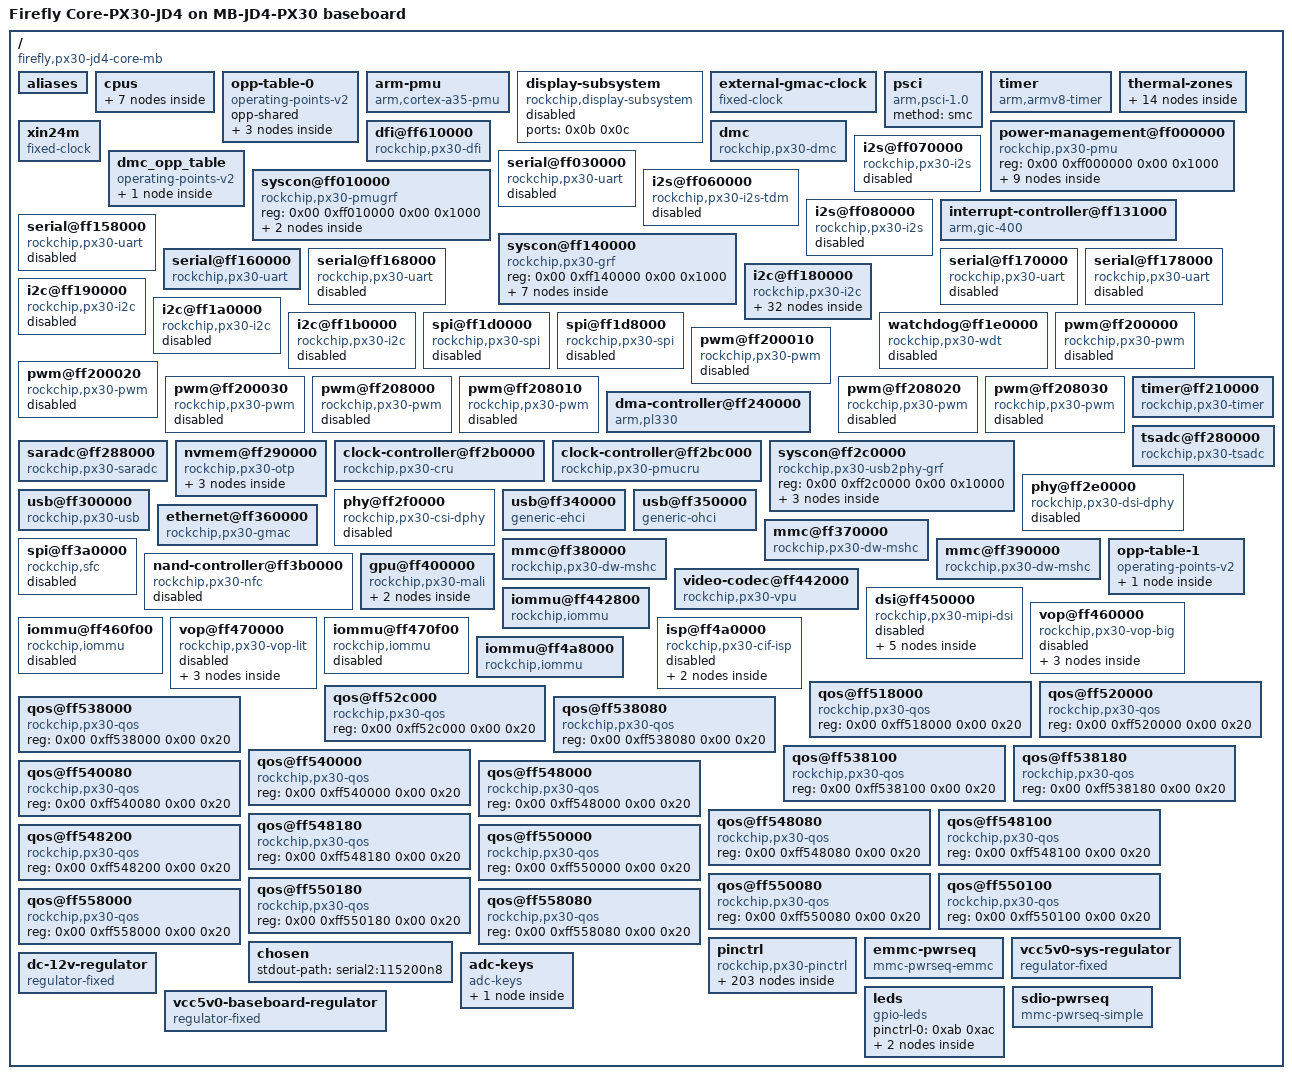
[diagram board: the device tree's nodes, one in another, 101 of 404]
/dts-v1/;

/ {
	compatible = "firefly,px30-jd4-core-mb\0firefly,px30-jd4-core\0rockchip,px30";
	interrupt-parent = <0x01>;
	#address-cells = <0x02>;
	#size-cells = <0x02>;
	model = "Firefly Core-PX30-JD4 on MB-JD4-PX30 baseboard";

	aliases {
		ethernet0 = "/ethernet@ff360000";
		i2c0 = "/i2c@ff180000";
		i2c1 = "/i2c@ff190000";
		i2c2 = "/i2c@ff1a0000";
		i2c3 = "/i2c@ff1b0000";
		serial0 = "/serial@ff030000";
		serial1 = "/serial@ff158000";
		serial2 = "/serial@ff160000";
		serial3 = "/serial@ff168000";
		serial4 = "/serial@ff170000";
		serial5 = "/serial@ff178000";
		spi0 = "/spi@ff1d0000";
		spi1 = "/spi@ff1d8000";
		mmc0 = "/mmc@ff370000";
		mmc1 = "/mmc@ff380000";
		mmc2 = "/mmc@ff390000";
	};

	cpus {
		#address-cells = <0x02>;
		#size-cells = <0x00>;

		cpu@0 {
			device_type = "cpu";
			compatible = "arm,cortex-a35";
			reg = <0x00 0x00>;
			enable-method = "psci";
			clocks = <0x02 0x07>;
			#cooling-cells = <0x02>;
			cpu-idle-states = <0x03 0x04>;
			dynamic-power-coefficient = <0x5a>;
			operating-points-v2 = <0x05>;
			cpu-supply = <0x06>;
			phandle = <0x07>;
		};

		cpu@1 {
			device_type = "cpu";
			compatible = "arm,cortex-a35";
			reg = <0x00 0x01>;
			enable-method = "psci";
			clocks = <0x02 0x07>;
			#cooling-cells = <0x02>;
			cpu-idle-states = <0x03 0x04>;
			dynamic-power-coefficient = <0x5a>;
			operating-points-v2 = <0x05>;
			cpu-supply = <0x06>;
			phandle = <0x08>;
		};

		cpu@2 {
			device_type = "cpu";
			compatible = "arm,cortex-a35";
			reg = <0x00 0x02>;
			enable-method = "psci";
			clocks = <0x02 0x07>;
			#cooling-cells = <0x02>;
			cpu-idle-states = <0x03 0x04>;
			dynamic-power-coefficient = <0x5a>;
			operating-points-v2 = <0x05>;
			cpu-supply = <0x06>;
			phandle = <0x09>;
		};

		cpu@3 {
			device_type = "cpu";
			compatible = "arm,cortex-a35";
			reg = <0x00 0x03>;
			enable-method = "psci";
			clocks = <0x02 0x07>;
			#cooling-cells = <0x02>;
			cpu-idle-states = <0x03 0x04>;
			dynamic-power-coefficient = <0x5a>;
			operating-points-v2 = <0x05>;
			cpu-supply = <0x06>;
			phandle = <0x0a>;
		};

		idle-states {
			entry-method = "psci";

			cpu-sleep {
				compatible = "arm,idle-state";
				local-timer-stop;
				arm,psci-suspend-param = <0x10000>;
				entry-latency-us = <0x78>;
				exit-latency-us = <0xfa>;
				min-residency-us = <0x384>;
				phandle = <0x03>;
			};

			cluster-sleep {
				compatible = "arm,idle-state";
				local-timer-stop;
				arm,psci-suspend-param = <0x1010000>;
				entry-latency-us = <0x190>;
				exit-latency-us = <0x1f4>;
				min-residency-us = <0x7d0>;
				phandle = <0x04>;
			};
		};
	};

	opp-table-0 {
		compatible = "operating-points-v2";
		opp-shared;
		phandle = <0x05>;

		opp-1008000000 {
			opp-hz = <0x00 0x3c14dc00>;
			opp-microvolt = <0x11edd8 0x11edd8 0x149970>;
			clock-latency-ns = <0x9c40>;
		};

		opp-1296000000 {
			opp-hz = <0x00 0x4d3f6400>;
			opp-microvolt = <0x149970 0x149970 0x149970>;
			clock-latency-ns = <0x9c40>;
		};

		opp-1416000000 {
			opp-hz = <0x00 0x54667200>;
			opp-microvolt = <0x149970 0x149970 0x149970>;
			clock-latency-ns = <0x9c40>;
			turbo-mode;
		};
	};

	arm-pmu {
		compatible = "arm,cortex-a35-pmu";
		interrupts = <0x00 0x64 0x04 0x00 0x65 0x04 0x00 0x66 0x04 0x00 0x67 0x04>;
		interrupt-affinity = <0x07 0x08 0x09 0x0a>;
	};

	display-subsystem {
		compatible = "rockchip,display-subsystem";
		ports = <0x0b 0x0c>;
		status = "disabled";
	};

	external-gmac-clock {
		compatible = "fixed-clock";
		clock-frequency = <0x2faf080>;
		clock-output-names = "gmac_clkin";
		#clock-cells = <0x00>;
	};

	psci {
		compatible = "arm,psci-1.0";
		method = "smc";
	};

	timer {
		compatible = "arm,armv8-timer";
		interrupts = <0x01 0x0d 0xf04 0x01 0x0e 0xf04 0x01 0x0b 0xf04 0x01 0x0a 0xf04>;
	};

	thermal-zones {

		soc-thermal {
			polling-delay-passive = <0x14>;
			polling-delay = <0x3e8>;
			sustainable-power = <0x2ee>;
			thermal-sensors = <0x0d 0x00>;

			trips {

				trip-point-0 {
					temperature = <0x11170>;
					hysteresis = <0x7d0>;
					type = "passive";
				};

				trip-point-1 {
					temperature = <0x14c08>;
					hysteresis = <0x7d0>;
					type = "passive";
					phandle = <0x0e>;
				};

				soc-crit {
					temperature = <0x1c138>;
					hysteresis = <0x7d0>;
					type = "critical";
				};
			};

			cooling-maps {

				map0 {
					trip = <0x0e>;
					cooling-device = <0x07 0xffffffff 0xffffffff>;
					contribution = <0x1000>;
				};
			};
		};

		gpu-thermal {
			polling-delay-passive = <0x64>;
			polling-delay = <0x3e8>;
			thermal-sensors = <0x0d 0x01>;

			trips {

				gpu-threshold {
					temperature = <0x11170>;
					hysteresis = <0x7d0>;
					type = "passive";
				};

				gpu-target {
					temperature = <0x14c08>;
					hysteresis = <0x7d0>;
					type = "passive";
					phandle = <0x0f>;
				};

				gpu-crit {
					temperature = <0x1c138>;
					hysteresis = <0x7d0>;
					type = "critical";
				};
			};

			cooling-maps {

				map0 {
					trip = <0x0f>;
					cooling-device = <0x10 0xffffffff 0xffffffff>;
				};
			};
		};
	};

	xin24m {
		compatible = "fixed-clock";
		#clock-cells = <0x00>;
		clock-frequency = <0x16e3600>;
		clock-output-names = "xin24m";
		phandle = <0x71>;
	};

	power-management@ff000000 {
		compatible = "rockchip,px30-pmu\0syscon\0simple-mfd";
		reg = <0x00 0xff000000 0x00 0x1000>;

		power-controller {
			compatible = "rockchip,px30-power-controller";
			#power-domain-cells = <0x01>;
			#address-cells = <0x01>;
			#size-cells = <0x00>;
			phandle = <0x73>;

			power-domain@5 {
				reg = <0x05>;
				clocks = <0x02 0x103 0x02 0x102 0x02 0x3c>;
				pm_qos = <0x11 0x12>;
				#power-domain-cells = <0x00>;
			};

			power-domain@7 {
				reg = <0x07>;
				clocks = <0x02 0xf7 0x02 0x3b>;
				pm_qos = <0x13>;
				#power-domain-cells = <0x00>;
			};

			power-domain@9 {
				reg = <0x09>;
				clocks = <0x02 0xb2 0x02 0x143 0x02 0x40 0x02 0x3f>;
				pm_qos = <0x14>;
				#power-domain-cells = <0x00>;
			};

			power-domain@10 {
				reg = <0x0a>;
				clocks = <0x02 0xfe 0x02 0x100 0x02 0xff 0x02 0x101 0x02 0x39 0x02 0x37 0x02 0x38 0x02 0x3a>;
				pm_qos = <0x15 0x16 0x17 0x18>;
				#power-domain-cells = <0x00>;
			};

			power-domain@11 {
				reg = <0x0b>;
				clocks = <0x02 0xaf 0x02 0xf4 0x02 0x4b>;
				pm_qos = <0x19 0x1a>;
				#power-domain-cells = <0x00>;
			};

			power-domain@12 {
				reg = <0x0c>;
				clocks = <0x02 0xb7 0x02 0xb5 0x02 0xb6 0x02 0x96 0x02 0x97 0x02 0xfd 0x02 0xfb 0x02 0xfc 0x02 0x144 0x02 0x35 0x02 0x36>;
				pm_qos = <0x1b 0x1c 0x1d 0x1e>;
				#power-domain-cells = <0x00>;
			};

			power-domain@13 {
				reg = <0x0d>;
				clocks = <0x02 0xb3 0x02 0xb4 0x02 0xf9 0x02 0xfa 0x02 0x33>;
				pm_qos = <0x1f 0x20 0x21 0x22 0x23>;
				#power-domain-cells = <0x00>;
			};

			power-domain@14 {
				reg = <0x0e>;
				clocks = <0x02 0x49>;
				pm_qos = <0x24>;
				#power-domain-cells = <0x00>;
			};
		};
	};

	dfi@ff610000 {
		reg = <0x00 0xff610000 0x00 0x400>;
		compatible = "rockchip,px30-dfi";
		rockchip,pmu = <0x25>;
		status = "okay";
		phandle = <0x26>;
	};

	dmc {
		compatible = "rockchip,px30-dmc";
		devfreq-events = <0x26>;
		clocks = <0x02 0x54>;
		clock-names = "dmc_clk";
		operating-points-v2 = <0x27>;
		uptreshold = <0x28>;
		downdifferential = <0x14>;
		status = "okay";
	};

	dmc_opp_table {
		compatible = "operating-points-v2";
		phandle = <0x27>;

		opp-924000000 {
			opp-hz = <0x00 0x37131f00>;
			opp-microvolt = <0x112a88>;
		};
	};

	syscon@ff010000 {
		compatible = "rockchip,px30-pmugrf\0syscon\0simple-mfd";
		reg = <0x00 0xff010000 0x00 0x1000>;
		#address-cells = <0x01>;
		#size-cells = <0x01>;
		phandle = <0x25>;

		io-domains {
			compatible = "rockchip,px30-pmu-io-voltage-domain";
			status = "okay";
			pmuio1-supply = <0x28>;
			pmuio2-supply = <0x28>;
		};

		reboot-mode {
			compatible = "syscon-reboot-mode";
			offset = <0x200>;
			mode-bootloader = <0x5242c301>;
			mode-fastboot = <0x5242c309>;
			mode-loader = <0x5242c301>;
			mode-normal = <0x5242c300>;
			mode-recovery = <0x5242c303>;
		};
	};

	serial@ff030000 {
		compatible = "rockchip,px30-uart\0snps,dw-apb-uart";
		reg = <0x00 0xff030000 0x00 0x100>;
		interrupts = <0x00 0x0f 0x04>;
		clocks = <0x29 0x06 0x29 0x15>;
		clock-names = "baudclk\0apb_pclk";
		dmas = <0x2a 0x00 0x2a 0x01>;
		dma-names = "tx\0rx";
		reg-shift = <0x02>;
		reg-io-width = <0x04>;
		pinctrl-names = "default";
		pinctrl-0 = <0x2b 0x2c 0x2d>;
		status = "disabled";
	};

	i2s@ff060000 {
		compatible = "rockchip,px30-i2s-tdm";
		reg = <0x00 0xff060000 0x00 0x1000>;
		interrupts = <0x00 0x0c 0x04>;
		clocks = <0x02 0x10 0x02 0x12 0x02 0x106>;
		clock-names = "mclk_tx\0mclk_rx\0hclk";
		dmas = <0x2a 0x10 0x2a 0x11>;
		dma-names = "tx\0rx";
		rockchip,grf = <0x2e>;
		resets = <0x02 0x84 0x02 0xbf>;
		reset-names = "tx-m\0rx-m";
		pinctrl-names = "default";
		pinctrl-0 = <0x2f 0x30 0x31 0x32 0x33 0x34 0x35 0x36 0x37 0x38 0x39 0x3a>;
		#sound-dai-cells = <0x00>;
		status = "disabled";
	};

	i2s@ff070000 {
		compatible = "rockchip,px30-i2s\0rockchip,rk3066-i2s";
		reg = <0x00 0xff070000 0x00 0x1000>;
		interrupts = <0x00 0x0d 0x04>;
		clocks = <0x02 0x14 0x02 0x107>;
		clock-names = "i2s_clk\0i2s_hclk";
		dmas = <0x2a 0x12 0x2a 0x13>;
		dma-names = "tx\0rx";
		pinctrl-names = "default";
		pinctrl-0 = <0x3b 0x3c 0x3d 0x3e>;
		#sound-dai-cells = <0x00>;
		status = "disabled";
	};

	i2s@ff080000 {
		compatible = "rockchip,px30-i2s\0rockchip,rk3066-i2s";
		reg = <0x00 0xff080000 0x00 0x1000>;
		interrupts = <0x00 0x0e 0x04>;
		clocks = <0x02 0x16 0x02 0x108>;
		clock-names = "i2s_clk\0i2s_hclk";
		dmas = <0x2a 0x14 0x2a 0x15>;
		dma-names = "tx\0rx";
		pinctrl-names = "default";
		pinctrl-0 = <0x3f 0x40 0x41 0x42>;
		#sound-dai-cells = <0x00>;
		status = "disabled";
	};

	interrupt-controller@ff131000 {
		compatible = "arm,gic-400";
		#interrupt-cells = <0x03>;
		#address-cells = <0x00>;
		interrupt-controller;
		reg = <0x00 0xff131000 0x00 0x1000 0x00 0xff132000 0x00 0x2000 0x00 0xff134000 0x00 0x2000 0x00 0xff136000 0x00 0x2000>;
		interrupts = <0x01 0x09 0xf04>;
		phandle = <0x01>;
	};

	syscon@ff140000 {
		compatible = "rockchip,px30-grf\0syscon\0simple-mfd";
		reg = <0x00 0xff140000 0x00 0x1000>;
		#address-cells = <0x01>;
		#size-cells = <0x01>;
		phandle = <0x2e>;

		io-domains {
			compatible = "rockchip,px30-io-voltage-domain";
			status = "okay";
			vccio1-supply = <0x43>;
			vccio2-supply = <0x44>;
			vccio3-supply = <0x45>;
			vccio4-supply = <0x28>;
			vccio5-supply = <0x45>;
			vccio6-supply = <0x43>;
		};

		lvds {
			compatible = "rockchip,px30-lvds";
			phys = <0x46>;
			phy-names = "dphy";
			rockchip,grf = <0x2e>;
			rockchip,output = "lvds";
			status = "disabled";

			ports {
				#address-cells = <0x01>;
				#size-cells = <0x00>;

				port@0 {
					reg = <0x00>;
					#address-cells = <0x01>;
					#size-cells = <0x00>;

					endpoint@0 {
						reg = <0x00>;
						remote-endpoint = <0x47>;
						phandle = <0x98>;
					};

					endpoint@1 {
						reg = <0x01>;
						remote-endpoint = <0x48>;
						phandle = <0x9b>;
					};
				};

				port@1 {
					reg = <0x01>;
				};
			};
		};
	};

	serial@ff158000 {
		compatible = "rockchip,px30-uart\0snps,dw-apb-uart";
		reg = <0x00 0xff158000 0x00 0x100>;
		interrupts = <0x00 0x10 0x04>;
		clocks = <0x02 0x18 0x02 0x149>;
		clock-names = "baudclk\0apb_pclk";
		dmas = <0x2a 0x02 0x2a 0x03>;
		dma-names = "tx\0rx";
		reg-shift = <0x02>;
		reg-io-width = <0x04>;
		pinctrl-names = "default";
		pinctrl-0 = <0x49 0x4a 0x4b>;
		status = "disabled";
	};

	serial@ff160000 {
		compatible = "rockchip,px30-uart\0snps,dw-apb-uart";
		reg = <0x00 0xff160000 0x00 0x100>;
		interrupts = <0x00 0x11 0x04>;
		clocks = <0x02 0x19 0x02 0x14a>;
		clock-names = "baudclk\0apb_pclk";
		dmas = <0x2a 0x04 0x2a 0x05>;
		dma-names = "tx\0rx";
		reg-shift = <0x02>;
		reg-io-width = <0x04>;
		pinctrl-names = "default";
		pinctrl-0 = <0x4c>;
		status = "okay";
	};

	serial@ff168000 {
		compatible = "rockchip,px30-uart\0snps,dw-apb-uart";
		reg = <0x00 0xff168000 0x00 0x100>;
		interrupts = <0x00 0x12 0x04>;
		clocks = <0x02 0x1a 0x02 0x14b>;
		clock-names = "baudclk\0apb_pclk";
		dmas = <0x2a 0x06 0x2a 0x07>;
		dma-names = "tx\0rx";
		reg-shift = <0x02>;
		reg-io-width = <0x04>;
		pinctrl-names = "default";
		pinctrl-0 = <0x4d 0x4e 0x4f>;
		status = "disabled";
	};

	serial@ff170000 {
		compatible = "rockchip,px30-uart\0snps,dw-apb-uart";
		reg = <0x00 0xff170000 0x00 0x100>;
		interrupts = <0x00 0x13 0x04>;
		clocks = <0x02 0x1b 0x02 0x14c>;
		clock-names = "baudclk\0apb_pclk";
		dmas = <0x2a 0x08 0x2a 0x09>;
		dma-names = "tx\0rx";
		reg-shift = <0x02>;
		reg-io-width = <0x04>;
		pinctrl-names = "default";
		pinctrl-0 = <0x50 0x51 0x52>;
		status = "disabled";
	};

	serial@ff178000 {
		compatible = "rockchip,px30-uart\0snps,dw-apb-uart";
		reg = <0x00 0xff178000 0x00 0x100>;
		interrupts = <0x00 0x14 0x04>;
		clocks = <0x02 0x1c 0x02 0x14d>;
		clock-names = "baudclk\0apb_pclk";
		dmas = <0x2a 0x0a 0x2a 0x0b>;
		dma-names = "tx\0rx";
		reg-shift = <0x02>;
		reg-io-width = <0x04>;
		pinctrl-names = "default";
		pinctrl-0 = <0x53 0x54 0x55>;
		status = "disabled";
	};

	i2c@ff180000 {
		compatible = "rockchip,px30-i2c\0rockchip,rk3399-i2c";
		reg = <0x00 0xff180000 0x00 0x1000>;
		clocks = <0x02 0x1d 0x02 0x14e>;
		clock-names = "i2c\0pclk";
		interrupts = <0x00 0x07 0x04>;
		pinctrl-names = "default";
		pinctrl-0 = <0x56>;
		#address-cells = <0x01>;
		#size-cells = <0x00>;
		status = "okay";

		pmic@20 {
			compatible = "rockchip,rk809";
			reg = <0x20>;
			interrupt-parent = <0x57>;
			interrupts = <0x07 0x08>;
			pinctrl-names = "default";
			pinctrl-0 = <0x58>;
			rockchip,system-power-controller;
			wakeup-source;
			#clock-cells = <0x00>;
			clock-output-names = "xin32k";
			vcc1-supply = <0x59>;
			vcc2-supply = <0x59>;
			vcc3-supply = <0x59>;
			vcc4-supply = <0x59>;
			vcc5-supply = <0x5a>;
			vcc6-supply = <0x5a>;
			vcc7-supply = <0x5a>;
			vcc8-supply = <0x5a>;
			vcc9-supply = <0x59>;

			regulators {

				DCDC_REG1 {
					regulator-name = "vdd_log";
					regulator-min-microvolt = <0xe7ef0>;
					regulator-max-microvolt = <0x149970>;
					regulator-ramp-delay = <0x1771>;
					regulator-always-on;
					regulator-boot-on;
					phandle = <0x92>;

					regulator-state-mem {
						regulator-on-in-suspend;
						regulator-suspend-microvolt = <0xe7ef0>;
					};
				};

				DCDC_REG2 {
					regulator-name = "vdd_arm";
					regulator-min-microvolt = <0xe7ef0>;
					regulator-max-microvolt = <0x149970>;
					regulator-ramp-delay = <0x1771>;
					regulator-always-on;
					regulator-boot-on;
					phandle = <0x06>;

					regulator-state-mem {
						regulator-off-in-suspend;
						regulator-suspend-microvolt = <0xe7ef0>;
					};
				};

				DCDC_REG3 {
					regulator-name = "vcc_ddr";
					regulator-always-on;
					regulator-boot-on;

					regulator-state-mem {
						regulator-on-in-suspend;
					};
				};

				DCDC_REG4 {
					regulator-name = "vcc_3v0";
					regulator-min-microvolt = <0x2dc6c0>;
					regulator-max-microvolt = <0x2dc6c0>;
					regulator-always-on;
					regulator-boot-on;
					phandle = <0x45>;

					regulator-state-mem {
						regulator-on-in-suspend;
						regulator-suspend-microvolt = <0x2dc6c0>;
					};
				};

				DCDC_REG5 {
					regulator-name = "vcc3v3_sys";
					regulator-min-microvolt = <0x325aa0>;
					regulator-max-microvolt = <0x325aa0>;
					regulator-always-on;
					regulator-boot-on;
					phandle = <0x5a>;

					regulator-state-mem {
						regulator-on-in-suspend;
						regulator-suspend-microvolt = <0x325aa0>;
					};
				};

				LDO_REG1 {
					regulator-name = "vcc_1v0";
					regulator-min-microvolt = <0xf4240>;
					regulator-max-microvolt = <0xf4240>;
					regulator-always-on;
					regulator-boot-on;

					regulator-state-mem {
						regulator-on-in-suspend;
						regulator-suspend-microvolt = <0xf4240>;
					};
				};

				LDO_REG2 {
					regulator-name = "vcc_1v8";
					regulator-min-microvolt = <0x1b7740>;
					regulator-max-microvolt = <0x1b7740>;
					regulator-always-on;
					regulator-boot-on;
					phandle = <0x43>;

					regulator-state-mem {
						regulator-on-in-suspend;
						regulator-suspend-microvolt = <0x1b7740>;
					};
				};

				LDO_REG3 {
					regulator-name = "vdd_1v0";
					regulator-min-microvolt = <0xf4240>;
					regulator-max-microvolt = <0xf4240>;
					regulator-always-on;
					regulator-boot-on;

					regulator-state-mem {
						regulator-on-in-suspend;
						regulator-suspend-microvolt = <0xf4240>;
					};
				};

				LDO_REG4 {
					regulator-name = "vcc3v0_pmu";
					regulator-min-microvolt = <0x2dc6c0>;
					regulator-max-microvolt = <0x2dc6c0>;
					regulator-always-on;
					regulator-boot-on;
					phandle = <0x28>;

					regulator-state-mem {
						regulator-on-in-suspend;
						regulator-suspend-microvolt = <0x2dc6c0>;
					};
				};

				LDO_REG5 {
					regulator-name = "vccio_sd";
					regulator-min-microvolt = <0x1b7740>;
					regulator-max-microvolt = <0x325aa0>;
					regulator-always-on;
					regulator-boot-on;
					phandle = <0x44>;

					regulator-state-mem {
						regulator-on-in-suspend;
						regulator-suspend-microvolt = <0x325aa0>;
					};
				};

				LDO_REG6 {
					regulator-name = "vcc_sd";
					regulator-min-microvolt = <0x325aa0>;
					regulator-max-microvolt = <0x325aa0>;
					regulator-boot-on;
					phandle = <0x7d>;

					regulator-state-mem {
						regulator-on-in-suspend;
						regulator-suspend-microvolt = <0x325aa0>;
					};
				};

				LDO_REG7 {
					regulator-name = "vcc2v8_dvp";
					regulator-min-microvolt = <0x2ab980>;
					regulator-max-microvolt = <0x2ab980>;
					regulator-boot-on;

					regulator-state-mem {
						regulator-off-in-suspend;
						regulator-suspend-microvolt = <0x2ab980>;
					};
				};

				LDO_REG8 {
					regulator-name = "vcc1v8_dvp";
					regulator-min-microvolt = <0x1b7740>;
					regulator-max-microvolt = <0x1b7740>;
					regulator-boot-on;

					regulator-state-mem {
						regulator-on-in-suspend;
						regulator-suspend-microvolt = <0x1b7740>;
					};
				};

				LDO_REG9 {
					regulator-name = "vcc1v5_dvp";
					regulator-min-microvolt = <0x16e360>;
					regulator-max-microvolt = <0x16e360>;
					regulator-boot-on;

					regulator-state-mem {
						regulator-off-in-suspend;
						regulator-suspend-microvolt = <0x16e360>;
					};
				};

				SWITCH_REG1 {
					regulator-name = "vcc3v3_lcd";
					regulator-boot-on;
				};

				SWITCH_REG2 {
					regulator-name = "vcc5v0_host";
					regulator-always-on;
					regulator-boot-on;
				};
			};
		};
	};

	i2c@ff190000 {
		compatible = "rockchip,px30-i2c\0rockchip,rk3399-i2c";
		reg = <0x00 0xff190000 0x00 0x1000>;
		clocks = <0x02 0x1e 0x02 0x14f>;
		clock-names = "i2c\0pclk";
		interrupts = <0x00 0x08 0x04>;
		pinctrl-names = "default";
		pinctrl-0 = <0x5b>;
		#address-cells = <0x01>;
		#size-cells = <0x00>;
		status = "disabled";
	};

	i2c@ff1a0000 {
		compatible = "rockchip,px30-i2c\0rockchip,rk3399-i2c";
		reg = <0x00 0xff1a0000 0x00 0x1000>;
		clocks = <0x02 0x1f 0x02 0x150>;
		clock-names = "i2c\0pclk";
		interrupts = <0x00 0x09 0x04>;
		pinctrl-names = "default";
		pinctrl-0 = <0x5c>;
		#address-cells = <0x01>;
		#size-cells = <0x00>;
		status = "disabled";
	};

	i2c@ff1b0000 {
		compatible = "rockchip,px30-i2c\0rockchip,rk3399-i2c";
		reg = <0x00 0xff1b0000 0x00 0x1000>;
		clocks = <0x02 0x20 0x02 0x151>;
		clock-names = "i2c\0pclk";
		interrupts = <0x00 0x0a 0x04>;
		pinctrl-names = "default";
		pinctrl-0 = <0x5d>;
		#address-cells = <0x01>;
		#size-cells = <0x00>;
		status = "disabled";
	};

	spi@ff1d0000 {
		compatible = "rockchip,px30-spi\0rockchip,rk3066-spi";
		reg = <0x00 0xff1d0000 0x00 0x1000>;
		interrupts = <0x00 0x1a 0x04>;
		clocks = <0x02 0x24 0x02 0x155>;
		clock-names = "spiclk\0apb_pclk";
		dmas = <0x2a 0x0c 0x2a 0x0d>;
		dma-names = "tx\0rx";
		num-cs = <0x02>;
		pinctrl-names = "default";
		pinctrl-0 = <0x5e 0x5f 0x60 0x61>;
		#address-cells = <0x01>;
		#size-cells = <0x00>;
		status = "disabled";
	};

	spi@ff1d8000 {
		compatible = "rockchip,px30-spi\0rockchip,rk3066-spi";
		reg = <0x00 0xff1d8000 0x00 0x1000>;
		interrupts = <0x00 0x1b 0x04>;
		clocks = <0x02 0x25 0x02 0x156>;
		clock-names = "spiclk\0apb_pclk";
		dmas = <0x2a 0x0e 0x2a 0x0f>;
		dma-names = "tx\0rx";
		num-cs = <0x02>;
		pinctrl-names = "default";
		pinctrl-0 = <0x62 0x63 0x64 0x65 0x66>;
		#address-cells = <0x01>;
		#size-cells = <0x00>;
		status = "disabled";
	};

	watchdog@ff1e0000 {
		compatible = "rockchip,px30-wdt\0snps,dw-wdt";
		reg = <0x00 0xff1e0000 0x00 0x100>;
		clocks = <0x02 0x15b>;
		interrupts = <0x00 0x25 0x04>;
		status = "disabled";
	};

	pwm@ff200000 {
		compatible = "rockchip,px30-pwm\0rockchip,rk3328-pwm";
		reg = <0x00 0xff200000 0x00 0x10>;
		clocks = <0x02 0x22 0x02 0x153>;
		clock-names = "pwm\0pclk";
		pinctrl-names = "default";
		pinctrl-0 = <0x67>;
		#pwm-cells = <0x03>;
		status = "disabled";
	};

	pwm@ff200010 {
		compatible = "rockchip,px30-pwm\0rockchip,rk3328-pwm";
		reg = <0x00 0xff200010 0x00 0x10>;
		clocks = <0x02 0x22 0x02 0x153>;
		clock-names = "pwm\0pclk";
		pinctrl-names = "default";
		pinctrl-0 = <0x68>;
		#pwm-cells = <0x03>;
		status = "disabled";
	};

	pwm@ff200020 {
		compatible = "rockchip,px30-pwm\0rockchip,rk3328-pwm";
		reg = <0x00 0xff200020 0x00 0x10>;
		clocks = <0x02 0x22 0x02 0x153>;
		clock-names = "pwm\0pclk";
		pinctrl-names = "default";
		pinctrl-0 = <0x69>;
		#pwm-cells = <0x03>;
		status = "disabled";
	};

	pwm@ff200030 {
		compatible = "rockchip,px30-pwm\0rockchip,rk3328-pwm";
		reg = <0x00 0xff200030 0x00 0x10>;
		clocks = <0x02 0x22 0x02 0x153>;
		clock-names = "pwm\0pclk";
		pinctrl-names = "default";
		pinctrl-0 = <0x6a>;
		#pwm-cells = <0x03>;
		status = "disabled";
	};

	pwm@ff208000 {
		compatible = "rockchip,px30-pwm\0rockchip,rk3328-pwm";
		reg = <0x00 0xff208000 0x00 0x10>;
		clocks = <0x02 0x23 0x02 0x154>;
		clock-names = "pwm\0pclk";
		pinctrl-names = "default";
		pinctrl-0 = <0x6b>;
		#pwm-cells = <0x03>;
		status = "disabled";
	};

	pwm@ff208010 {
		compatible = "rockchip,px30-pwm\0rockchip,rk3328-pwm";
		reg = <0x00 0xff208010 0x00 0x10>;
		clocks = <0x02 0x23 0x02 0x154>;
		clock-names = "pwm\0pclk";
		pinctrl-names = "default";
		pinctrl-0 = <0x6c>;
		#pwm-cells = <0x03>;
		status = "disabled";
	};

	pwm@ff208020 {
		compatible = "rockchip,px30-pwm\0rockchip,rk3328-pwm";
		reg = <0x00 0xff208020 0x00 0x10>;
		clocks = <0x02 0x23 0x02 0x154>;
		clock-names = "pwm\0pclk";
		pinctrl-names = "default";
		pinctrl-0 = <0x6d>;
		#pwm-cells = <0x03>;
		status = "disabled";
	};

	pwm@ff208030 {
		compatible = "rockchip,px30-pwm\0rockchip,rk3328-pwm";
		reg = <0x00 0xff208030 0x00 0x10>;
		clocks = <0x02 0x23 0x02 0x154>;
		clock-names = "pwm\0pclk";
		pinctrl-names = "default";
		pinctrl-0 = <0x6e>;
		#pwm-cells = <0x03>;
		status = "disabled";
	};

	timer@ff210000 {
		compatible = "rockchip,px30-timer\0rockchip,rk3288-timer";
		reg = <0x00 0xff210000 0x00 0x1000>;
		interrupts = <0x00 0x1e 0x04>;
		clocks = <0x02 0x159 0x02 0x26>;
		clock-names = "pclk\0timer";
	};

	dma-controller@ff240000 {
		compatible = "arm,pl330\0arm,primecell";
		reg = <0x00 0xff240000 0x00 0x4000>;
		interrupts = <0x00 0x01 0x04 0x00 0x02 0x04>;
		arm,pl330-periph-burst;
		clocks = <0x02 0xbb>;
		clock-names = "apb_pclk";
		#dma-cells = <0x01>;
		phandle = <0x2a>;
	};

	tsadc@ff280000 {
		compatible = "rockchip,px30-tsadc";
		reg = <0x00 0xff280000 0x00 0x100>;
		interrupts = <0x00 0x24 0x04>;
		assigned-clocks = <0x02 0x2c>;
		assigned-clock-rates = <0xc350>;
		clocks = <0x02 0x2c 0x02 0x158>;
		clock-names = "tsadc\0apb_pclk";
		resets = <0x02 0xa8>;
		reset-names = "tsadc-apb";
		rockchip,grf = <0x2e>;
		rockchip,hw-tshut-temp = <0x1d4c0>;
		pinctrl-names = "init\0default\0sleep";
		pinctrl-0 = <0x6f>;
		pinctrl-1 = <0x70>;
		pinctrl-2 = <0x6f>;
		#thermal-sensor-cells = <0x01>;
		status = "okay";
		rockchip,hw-tshut-mode = <0x01>;
		rockchip,hw-tshut-polarity = <0x01>;
		phandle = <0x0d>;
	};

	saradc@ff288000 {
		compatible = "rockchip,px30-saradc\0rockchip,rk3399-saradc";
		reg = <0x00 0xff288000 0x00 0x100>;
		interrupts = <0x00 0x54 0x04>;
		#io-channel-cells = <0x01>;
		clocks = <0x02 0x2d 0x02 0x157>;
		clock-names = "saradc\0apb_pclk";
		resets = <0x02 0xa5>;
		reset-names = "saradc-apb";
		status = "okay";
		vref-supply = <0x43>;
		phandle = <0xaa>;
	};

	nvmem@ff290000 {
		compatible = "rockchip,px30-otp";
		reg = <0x00 0xff290000 0x00 0x4000>;
		clocks = <0x02 0x2f 0x02 0x15a 0x02 0x161>;
		clock-names = "otp\0apb_pclk\0phy";
		resets = <0x02 0xb4>;
		reset-names = "phy";
		#address-cells = <0x01>;
		#size-cells = <0x01>;

		id@7 {
			reg = <0x07 0x10>;
		};

		cpu-leakage@17 {
			reg = <0x17 0x01>;
		};

		performance@1e {
			reg = <0x1e 0x01>;
			bits = <0x04 0x03>;
		};
	};

	clock-controller@ff2b0000 {
		compatible = "rockchip,px30-cru";
		reg = <0x00 0xff2b0000 0x00 0x1000>;
		clocks = <0x71 0x29 0x01>;
		clock-names = "xin24m\0gpll";
		rockchip,grf = <0x2e>;
		#clock-cells = <0x01>;
		#reset-cells = <0x01>;
		assigned-clocks = <0x02 0x04 0x02 0xab 0x02 0xb0 0x02 0xf0 0x02 0xf5 0x02 0x140 0x02 0x49>;
		assigned-clock-rates = <0x46cf7100 0xbebc200 0xbebc200 0x8f0d180 0x8f0d180 0x5f5e100 0xbebc200>;
		phandle = <0x02>;
	};

	clock-controller@ff2bc000 {
		compatible = "rockchip,px30-pmucru";
		reg = <0x00 0xff2bc000 0x00 0x1000>;
		clocks = <0x71>;
		clock-names = "xin24m";
		rockchip,grf = <0x2e>;
		#clock-cells = <0x01>;
		#reset-cells = <0x01>;
		assigned-clocks = <0x29 0x01 0x29 0x08 0x29 0x05>;
		assigned-clock-rates = <0x47868c00 0x5f5e100 0x18cba80>;
		phandle = <0x29>;
	};

	syscon@ff2c0000 {
		compatible = "rockchip,px30-usb2phy-grf\0syscon\0simple-mfd";
		reg = <0x00 0xff2c0000 0x00 0x10000>;
		#address-cells = <0x01>;
		#size-cells = <0x01>;

		usb2phy@100 {
			compatible = "rockchip,px30-usb2phy";
			reg = <0x100 0x20>;
			clocks = <0x29 0x0a>;
			clock-names = "phyclk";
			#clock-cells = <0x00>;
			assigned-clocks = <0x02 0x0e>;
			assigned-clock-parents = <0x72>;
			clock-output-names = "usb480m_phy";
			status = "okay";
			phandle = <0x72>;

			host-port {
				#phy-cells = <0x00>;
				interrupts = <0x00 0x44 0x04>;
				interrupt-names = "linestate";
				status = "okay";
				phandle = <0x75>;
			};

			otg-port {
				#phy-cells = <0x00>;
				interrupts = <0x00 0x42 0x04 0x00 0x41 0x04 0x00 0x40 0x04>;
				interrupt-names = "otg-bvalid\0otg-id\0linestate";
				status = "okay";
				phandle = <0x74>;
			};
		};
	};

	phy@ff2e0000 {
		compatible = "rockchip,px30-dsi-dphy";
		reg = <0x00 0xff2e0000 0x00 0x10000>;
		clocks = <0x29 0x0b 0x02 0x145>;
		clock-names = "ref\0pclk";
		resets = <0x02 0x3e>;
		reset-names = "apb";
		#phy-cells = <0x00>;
		power-domains = <0x73 0x0c>;
		status = "disabled";
		phandle = <0x46>;
	};

	phy@ff2f0000 {
		compatible = "rockchip,px30-csi-dphy";
		reg = <0x00 0xff2f0000 0x00 0x4000>;
		clocks = <0x02 0x146>;
		clock-names = "pclk";
		#phy-cells = <0x00>;
		power-domains = <0x73 0x0d>;
		resets = <0x02 0x2f>;
		reset-names = "apb";
		rockchip,grf = <0x2e>;
		status = "disabled";
		phandle = <0x9d>;
	};

	usb@ff300000 {
		compatible = "rockchip,px30-usb\0rockchip,rk3066-usb\0snps,dwc2";
		reg = <0x00 0xff300000 0x00 0x40000>;
		interrupts = <0x00 0x3e 0x04>;
		clocks = <0x02 0x102>;
		clock-names = "otg";
		dr_mode = "otg";
		usb-role-switch;
		role-switch-default-mode = "host";
		g-np-tx-fifo-size = <0x10>;
		g-rx-fifo-size = <0x118>;
		g-tx-fifo-size = <0x100 0x80 0x80 0x40 0x20 0x10>;
		phys = <0x74>;
		phy-names = "usb2-phy";
		power-domains = <0x73 0x05>;
		status = "okay";
	};

	usb@ff340000 {
		compatible = "generic-ehci";
		reg = <0x00 0xff340000 0x00 0x10000>;
		interrupts = <0x00 0x3c 0x04>;
		clocks = <0x02 0x103>;
		phys = <0x75>;
		phy-names = "usb";
		power-domains = <0x73 0x05>;
		status = "okay";
	};

	usb@ff350000 {
		compatible = "generic-ohci";
		reg = <0x00 0xff350000 0x00 0x10000>;
		interrupts = <0x00 0x3d 0x04>;
		clocks = <0x02 0x103>;
		phys = <0x75>;
		phy-names = "usb";
		power-domains = <0x73 0x05>;
		status = "okay";
	};

	ethernet@ff360000 {
		compatible = "rockchip,px30-gmac";
		reg = <0x00 0xff360000 0x00 0x10000>;
		interrupts = <0x00 0x2b 0x04>;
		interrupt-names = "macirq";
		clocks = <0x02 0x3e 0x02 0x3f 0x02 0x3f 0x02 0x40 0x02 0x41 0x02 0xb2 0x02 0x143 0x02 0x4c>;
		clock-names = "stmmaceth\0mac_clk_rx\0mac_clk_tx\0clk_mac_ref\0clk_mac_refout\0aclk_mac\0pclk_mac\0clk_mac_speed";
		rockchip,grf = <0x2e>;
		phy-mode = "rmii";
		pinctrl-names = "default";
		pinctrl-0 = <0x76 0x77>;
		power-domains = <0x73 0x09>;
		resets = <0x02 0x5e>;
		reset-names = "stmmaceth";
		status = "okay";
		clock_in_out = "output";
		phy-supply = <0x45>;
		snps,reset-gpio = <0x78 0x0d 0x01>;
		snps,reset-active-low;
		snps,reset-delays-us = <0x00 0xc350 0xc350>;
	};

	mmc@ff370000 {
		compatible = "rockchip,px30-dw-mshc\0rockchip,rk3288-dw-mshc";
		reg = <0x00 0xff370000 0x00 0x4000>;
		interrupts = <0x00 0x36 0x04>;
		clocks = <0x02 0xf7 0x02 0x3b 0x02 0x43 0x02 0x44>;
		clock-names = "biu\0ciu\0ciu-drive\0ciu-sample";
		bus-width = <0x04>;
		fifo-depth = <0x100>;
		max-frequency = <0x8f0d180>;
		pinctrl-names = "default";
		pinctrl-0 = <0x79 0x7a 0x7b 0x7c>;
		power-domains = <0x73 0x07>;
		status = "okay";
		cap-mmc-highspeed;
		cap-sd-highspeed;
		card-detect-delay = <0x320>;
		sd-uhs-sdr12;
		sd-uhs-sdr25;
		sd-uhs-sdr50;
		sd-uhs-sdr104;
		vmmc-supply = <0x7d>;
		vqmmc-supply = <0x44>;
	};

	mmc@ff380000 {
		compatible = "rockchip,px30-dw-mshc\0rockchip,rk3288-dw-mshc";
		reg = <0x00 0xff380000 0x00 0x4000>;
		interrupts = <0x00 0x37 0x04>;
		clocks = <0x02 0xff 0x02 0x38 0x02 0x45 0x02 0x46>;
		clock-names = "biu\0ciu\0ciu-drive\0ciu-sample";
		bus-width = <0x04>;
		fifo-depth = <0x100>;
		max-frequency = <0x8f0d180>;
		pinctrl-names = "default";
		pinctrl-0 = <0x7e 0x7f 0x80>;
		power-domains = <0x73 0x0a>;
		status = "okay";
		cap-sd-highspeed;
		keep-power-in-suspend;
		non-removable;
		mmc-pwrseq = <0x81>;
		sd-uhs-sdr104;
	};

	mmc@ff390000 {
		compatible = "rockchip,px30-dw-mshc\0rockchip,rk3288-dw-mshc";
		reg = <0x00 0xff390000 0x00 0x4000>;
		interrupts = <0x00 0x35 0x04>;
		clocks = <0x02 0x100 0x02 0x39 0x02 0x47 0x02 0x48>;
		clock-names = "biu\0ciu\0ciu-drive\0ciu-sample";
		bus-width = <0x08>;
		fifo-depth = <0x100>;
		max-frequency = <0x8f0d180>;
		pinctrl-names = "default";
		pinctrl-0 = <0x82 0x83 0x84>;
		power-domains = <0x73 0x0a>;
		status = "okay";
		cap-mmc-highspeed;
		mmc-hs200-1_8v;
		non-removable;
		mmc-pwrseq = <0x85>;
		vmmc-supply = <0x45>;
		vqmmc-supply = <0x43>;
	};

	spi@ff3a0000 {
		compatible = "rockchip,sfc";
		reg = <0x00 0xff3a0000 0x00 0x4000>;
		interrupts = <0x00 0x38 0x04>;
		clocks = <0x02 0x3a 0x02 0x101>;
		clock-names = "clk_sfc\0hclk_sfc";
		pinctrl-0 = <0x86 0x87 0x88>;
		pinctrl-names = "default";
		power-domains = <0x73 0x0a>;
		status = "disabled";
	};

	nand-controller@ff3b0000 {
		compatible = "rockchip,px30-nfc";
		reg = <0x00 0xff3b0000 0x00 0x4000>;
		interrupts = <0x00 0x39 0x04>;
		clocks = <0x02 0xfe 0x02 0x37>;
		clock-names = "ahb\0nfc";
		assigned-clocks = <0x02 0x37>;
		assigned-clock-rates = <0x8f0d180>;
		pinctrl-names = "default";
		pinctrl-0 = <0x89 0x8a 0x8b 0x8c 0x8d 0x8e 0x8f 0x90>;
		power-domains = <0x73 0x0a>;
		status = "disabled";
	};

	opp-table-1 {
		compatible = "operating-points-v2";
		phandle = <0x91>;

		opp-560000000 {
			opp-hz = <0x00 0x2160ec00>;
			opp-microvolt = <0x118c30>;
		};
	};

	gpu@ff400000 {
		compatible = "rockchip,px30-mali\0arm,mali-bifrost";
		reg = <0x00 0xff400000 0x00 0x4000>;
		interrupts = <0x00 0x2f 0x04 0x00 0x2e 0x04 0x00 0x2d 0x04>;
		interrupt-names = "job\0mmu\0gpu";
		clocks = <0x02 0x49>;
		clock-names = "bus";
		resets = <0x02 0x12>;
		#cooling-cells = <0x02>;
		power-domains = <0x73 0x0e>;
		power_policy = "coarse_demand";
		operating-points-v2 = <0x91>;
		status = "okay";
		mali-supply = <0x92>;
		phandle = <0x10>;

		power_model@0 {
			compatible = "arm,mali-simple-power-model";
			static-coefficient = <0x186a0>;
			dynamic-coefficient = <0x3b9>;
			ts = <0xfffe56a6 0xf87a 0xfffffab5 0x14>;
			thermal-zone = "gpu-thermal";
		};

		power_model@1 {
			compatible = "arm,mali-g31-power-model";
			scale = <0x05>;
		};
	};

	video-codec@ff442000 {
		compatible = "rockchip,px30-vpu";
		reg = <0x00 0xff442000 0x00 0x800>;
		interrupts = <0x00 0x50 0x04 0x00 0x4f 0x04>;
		interrupt-names = "vepu\0vdpu";
		clocks = <0x02 0xaf 0x02 0xf4>;
		clock-names = "aclk\0hclk";
		iommus = <0x93>;
		power-domains = <0x73 0x0b>;
	};

	iommu@ff442800 {
		compatible = "rockchip,iommu";
		reg = <0x00 0xff442800 0x00 0x100>;
		interrupts = <0x00 0x51 0x04>;
		clocks = <0x02 0xaf 0x02 0xf4>;
		clock-names = "aclk\0iface";
		#iommu-cells = <0x00>;
		power-domains = <0x73 0x0b>;
		phandle = <0x93>;
	};

	dsi@ff450000 {
		compatible = "rockchip,px30-mipi-dsi\0snps,dw-mipi-dsi";
		reg = <0x00 0xff450000 0x00 0x10000>;
		interrupts = <0x00 0x4b 0x04>;
		clocks = <0x02 0x144>;
		clock-names = "pclk";
		phys = <0x46>;
		phy-names = "dphy";
		power-domains = <0x73 0x0c>;
		resets = <0x02 0x3d>;
		reset-names = "apb";
		rockchip,grf = <0x2e>;
		#address-cells = <0x01>;
		#size-cells = <0x00>;
		status = "disabled";

		ports {
			#address-cells = <0x01>;
			#size-cells = <0x00>;

			port@0 {
				reg = <0x00>;
				#address-cells = <0x01>;
				#size-cells = <0x00>;

				endpoint@0 {
					reg = <0x00>;
					remote-endpoint = <0x94>;
					phandle = <0x97>;
				};

				endpoint@1 {
					reg = <0x01>;
					remote-endpoint = <0x95>;
					phandle = <0x9a>;
				};
			};

			port@1 {
				reg = <0x01>;
			};
		};
	};

	vop@ff460000 {
		compatible = "rockchip,px30-vop-big";
		reg = <0x00 0xff460000 0x00 0xefc>;
		interrupts = <0x00 0x4d 0x04>;
		clocks = <0x02 0xb5 0x02 0x96 0x02 0xfb>;
		clock-names = "aclk_vop\0dclk_vop\0hclk_vop";
		resets = <0x02 0x33 0x02 0x34 0x02 0x35>;
		reset-names = "axi\0ahb\0dclk";
		iommus = <0x96>;
		power-domains = <0x73 0x0c>;
		status = "disabled";

		port {
			#address-cells = <0x01>;
			#size-cells = <0x00>;
			phandle = <0x0b>;

			endpoint@0 {
				reg = <0x00>;
				remote-endpoint = <0x97>;
				phandle = <0x94>;
			};

			endpoint@1 {
				reg = <0x01>;
				remote-endpoint = <0x98>;
				phandle = <0x47>;
			};
		};
	};

	iommu@ff460f00 {
		compatible = "rockchip,iommu";
		reg = <0x00 0xff460f00 0x00 0x100>;
		interrupts = <0x00 0x4d 0x04>;
		clocks = <0x02 0xb5 0x02 0xfb>;
		clock-names = "aclk\0iface";
		power-domains = <0x73 0x0c>;
		#iommu-cells = <0x00>;
		status = "disabled";
		phandle = <0x96>;
	};

	vop@ff470000 {
		compatible = "rockchip,px30-vop-lit";
		reg = <0x00 0xff470000 0x00 0xefc>;
		interrupts = <0x00 0x4e 0x04>;
		clocks = <0x02 0xb6 0x02 0x97 0x02 0xfc>;
		clock-names = "aclk_vop\0dclk_vop\0hclk_vop";
		resets = <0x02 0x37 0x02 0x38 0x02 0x39>;
		reset-names = "axi\0ahb\0dclk";
		iommus = <0x99>;
		power-domains = <0x73 0x0c>;
		status = "disabled";

		port {
			#address-cells = <0x01>;
			#size-cells = <0x00>;
			phandle = <0x0c>;

			endpoint@0 {
				reg = <0x00>;
				remote-endpoint = <0x9a>;
				phandle = <0x95>;
			};

			endpoint@1 {
				reg = <0x01>;
				remote-endpoint = <0x9b>;
				phandle = <0x48>;
			};
		};
	};

	iommu@ff470f00 {
		compatible = "rockchip,iommu";
		reg = <0x00 0xff470f00 0x00 0x100>;
		interrupts = <0x00 0x4e 0x04>;
		clocks = <0x02 0xb6 0x02 0xfc>;
		clock-names = "aclk\0iface";
		power-domains = <0x73 0x0c>;
		#iommu-cells = <0x00>;
		status = "disabled";
		phandle = <0x99>;
	};

	isp@ff4a0000 {
		compatible = "rockchip,px30-cif-isp";
		reg = <0x00 0xff4a0000 0x00 0x8000>;
		interrupts = <0x00 0x46 0x04 0x00 0x49 0x04 0x00 0x4a 0x04>;
		interrupt-names = "isp\0mi\0mipi";
		clocks = <0x02 0x33 0x02 0xb4 0x02 0xfa 0x02 0x15f>;
		clock-names = "isp\0aclk\0hclk\0pclk";
		iommus = <0x9c>;
		phys = <0x9d>;
		phy-names = "dphy";
		power-domains = <0x73 0x0d>;
		status = "disabled";

		ports {
			#address-cells = <0x01>;
			#size-cells = <0x00>;

			port@0 {
				reg = <0x00>;
				#address-cells = <0x01>;
				#size-cells = <0x00>;
			};
		};
	};

	iommu@ff4a8000 {
		compatible = "rockchip,iommu";
		reg = <0x00 0xff4a8000 0x00 0x100>;
		interrupts = <0x00 0x46 0x04>;
		clocks = <0x02 0xb4 0x02 0xfa>;
		clock-names = "aclk\0iface";
		power-domains = <0x73 0x0d>;
		rockchip,disable-mmu-reset;
		#iommu-cells = <0x00>;
		phandle = <0x9c>;
	};

	qos@ff518000 {
		compatible = "rockchip,px30-qos\0syscon";
		reg = <0x00 0xff518000 0x00 0x20>;
		phandle = <0x14>;
	};

	qos@ff520000 {
		compatible = "rockchip,px30-qos\0syscon";
		reg = <0x00 0xff520000 0x00 0x20>;
		phandle = <0x24>;
	};

	qos@ff52c000 {
		compatible = "rockchip,px30-qos\0syscon";
		reg = <0x00 0xff52c000 0x00 0x20>;
		phandle = <0x13>;
	};

	qos@ff538000 {
		compatible = "rockchip,px30-qos\0syscon";
		reg = <0x00 0xff538000 0x00 0x20>;
		phandle = <0x15>;
	};

	qos@ff538080 {
		compatible = "rockchip,px30-qos\0syscon";
		reg = <0x00 0xff538080 0x00 0x20>;
		phandle = <0x16>;
	};

	qos@ff538100 {
		compatible = "rockchip,px30-qos\0syscon";
		reg = <0x00 0xff538100 0x00 0x20>;
		phandle = <0x17>;
	};

	qos@ff538180 {
		compatible = "rockchip,px30-qos\0syscon";
		reg = <0x00 0xff538180 0x00 0x20>;
		phandle = <0x18>;
	};

	qos@ff540000 {
		compatible = "rockchip,px30-qos\0syscon";
		reg = <0x00 0xff540000 0x00 0x20>;
		phandle = <0x11>;
	};

	qos@ff540080 {
		compatible = "rockchip,px30-qos\0syscon";
		reg = <0x00 0xff540080 0x00 0x20>;
		phandle = <0x12>;
	};

	qos@ff548000 {
		compatible = "rockchip,px30-qos\0syscon";
		reg = <0x00 0xff548000 0x00 0x20>;
		phandle = <0x1f>;
	};

	qos@ff548080 {
		compatible = "rockchip,px30-qos\0syscon";
		reg = <0x00 0xff548080 0x00 0x20>;
		phandle = <0x20>;
	};

	qos@ff548100 {
		compatible = "rockchip,px30-qos\0syscon";
		reg = <0x00 0xff548100 0x00 0x20>;
		phandle = <0x21>;
	};

	qos@ff548180 {
		compatible = "rockchip,px30-qos\0syscon";
		reg = <0x00 0xff548180 0x00 0x20>;
		phandle = <0x22>;
	};

	qos@ff548200 {
		compatible = "rockchip,px30-qos\0syscon";
		reg = <0x00 0xff548200 0x00 0x20>;
		phandle = <0x23>;
	};

	qos@ff550000 {
		compatible = "rockchip,px30-qos\0syscon";
		reg = <0x00 0xff550000 0x00 0x20>;
		phandle = <0x1b>;
	};

	qos@ff550080 {
		compatible = "rockchip,px30-qos\0syscon";
		reg = <0x00 0xff550080 0x00 0x20>;
		phandle = <0x1c>;
	};

	qos@ff550100 {
		compatible = "rockchip,px30-qos\0syscon";
		reg = <0x00 0xff550100 0x00 0x20>;
		phandle = <0x1d>;
	};

	qos@ff550180 {
		compatible = "rockchip,px30-qos\0syscon";
		reg = <0x00 0xff550180 0x00 0x20>;
		phandle = <0x1e>;
	};

	qos@ff558000 {
		compatible = "rockchip,px30-qos\0syscon";
		reg = <0x00 0xff558000 0x00 0x20>;
		phandle = <0x19>;
	};

	qos@ff558080 {
		compatible = "rockchip,px30-qos\0syscon";
		reg = <0x00 0xff558080 0x00 0x20>;
		phandle = <0x1a>;
	};

	pinctrl {
		compatible = "rockchip,px30-pinctrl";
		rockchip,grf = <0x2e>;
		rockchip,pmu = <0x25>;
		#address-cells = <0x02>;
		#size-cells = <0x02>;
		ranges;

		gpio@ff040000 {
			compatible = "rockchip,gpio-bank";
			reg = <0x00 0xff040000 0x00 0x100>;
			interrupts = <0x00 0x03 0x04>;
			clocks = <0x29 0x14>;
			gpio-controller;
			#gpio-cells = <0x02>;
			interrupt-controller;
			#interrupt-cells = <0x02>;
			phandle = <0x57>;
		};

		gpio@ff250000 {
			compatible = "rockchip,gpio-bank";
			reg = <0x00 0xff250000 0x00 0x100>;
			interrupts = <0x00 0x04 0x04>;
			clocks = <0x02 0x15c>;
			gpio-controller;
			#gpio-cells = <0x02>;
			interrupt-controller;
			#interrupt-cells = <0x02>;
			phandle = <0xa8>;
		};

		gpio@ff260000 {
			compatible = "rockchip,gpio-bank";
			reg = <0x00 0xff260000 0x00 0x100>;
			interrupts = <0x00 0x05 0x04>;
			clocks = <0x02 0x15d>;
			gpio-controller;
			#gpio-cells = <0x02>;
			interrupt-controller;
			#interrupt-cells = <0x02>;
			phandle = <0x78>;
		};

		gpio@ff270000 {
			compatible = "rockchip,gpio-bank";
			reg = <0x00 0xff270000 0x00 0x100>;
			interrupts = <0x00 0x06 0x04>;
			clocks = <0x02 0x15e>;
			gpio-controller;
			#gpio-cells = <0x02>;
			interrupt-controller;
			#interrupt-cells = <0x02>;
		};

		pcfg-pull-up {
			bias-pull-up;
			phandle = <0xa0>;
		};

		pcfg-pull-down {
			bias-pull-down;
		};

		pcfg-pull-none {
			bias-disable;
			phandle = <0x9f>;
		};

		pcfg-pull-none-2ma {
			bias-disable;
			drive-strength = <0x02>;
		};

		pcfg-pull-up-2ma {
			bias-pull-up;
			drive-strength = <0x02>;
		};

		pcfg-pull-up-4ma {
			bias-pull-up;
			drive-strength = <0x04>;
			phandle = <0xa1>;
		};

		pcfg-pull-none-4ma {
			bias-disable;
			drive-strength = <0x04>;
		};

		pcfg-pull-down-4ma {
			bias-pull-down;
			drive-strength = <0x04>;
		};

		pcfg-pull-none-8ma {
			bias-disable;
			drive-strength = <0x08>;
			phandle = <0xa4>;
		};

		pcfg-pull-up-8ma {
			bias-pull-up;
			drive-strength = <0x08>;
			phandle = <0xa2>;
		};

		pcfg-pull-none-12ma {
			bias-disable;
			drive-strength = <0x0c>;
			phandle = <0xa6>;
		};

		pcfg-pull-up-12ma {
			bias-pull-up;
			drive-strength = <0x0c>;
			phandle = <0xa5>;
		};

		pcfg-pull-none-smt {
			bias-disable;
			input-schmitt-enable;
			phandle = <0x9e>;
		};

		pcfg-output-high {
			output-high;
		};

		pcfg-output-low {
			output-low;
		};

		pcfg-input-high {
			bias-pull-up;
			input-enable;
			phandle = <0xa3>;
		};

		pcfg-input {
			input-enable;
		};

		i2c0 {

			i2c0-xfer {
				rockchip,pins = <0x00 0x08 0x01 0x9e 0x00 0x09 0x01 0x9e>;
				phandle = <0x56>;
			};
		};

		i2c1 {

			i2c1-xfer {
				rockchip,pins = <0x00 0x12 0x01 0x9e 0x00 0x13 0x01 0x9e>;
				phandle = <0x5b>;
			};
		};

		i2c2 {

			i2c2-xfer {
				rockchip,pins = <0x02 0x0f 0x02 0x9e 0x02 0x10 0x02 0x9e>;
				phandle = <0x5c>;
			};
		};

		i2c3 {

			i2c3-xfer {
				rockchip,pins = <0x01 0x0c 0x04 0x9e 0x01 0x0d 0x04 0x9e>;
				phandle = <0x5d>;
			};
		};

		tsadc {

			tsadc-otp-pin {
				rockchip,pins = <0x00 0x06 0x00 0x9f>;
				phandle = <0x6f>;
			};

			tsadc-otp-out {
				rockchip,pins = <0x00 0x06 0x01 0x9f>;
				phandle = <0x70>;
			};
		};

		uart0 {

			uart0-xfer {
				rockchip,pins = <0x00 0x0a 0x01 0xa0 0x00 0x0b 0x01 0xa0>;
				phandle = <0x2b>;
			};

			uart0-cts {
				rockchip,pins = <0x00 0x0c 0x01 0x9f>;
				phandle = <0x2c>;
			};

			uart0-rts {
				rockchip,pins = <0x00 0x0d 0x01 0x9f>;
				phandle = <0x2d>;
			};
		};

		uart1 {

			uart1-xfer {
				rockchip,pins = <0x01 0x11 0x01 0xa0 0x01 0x10 0x01 0xa0>;
				phandle = <0x49>;
			};

			uart1-cts {
				rockchip,pins = <0x01 0x12 0x01 0x9f>;
				phandle = <0x4a>;
			};

			uart1-rts {
				rockchip,pins = <0x01 0x13 0x01 0x9f>;
				phandle = <0x4b>;
			};
		};

		uart2-m0 {

			uart2m0-xfer {
				rockchip,pins = <0x01 0x1a 0x02 0xa0 0x01 0x1b 0x02 0xa0>;
			};
		};

		uart2-m1 {

			uart2m1-xfer {
				rockchip,pins = <0x02 0x0c 0x02 0xa0 0x02 0x0e 0x02 0xa0>;
				phandle = <0x4c>;
			};
		};

		uart3-m0 {

			uart3m0-xfer {
				rockchip,pins = <0x00 0x10 0x02 0xa0 0x00 0x11 0x02 0xa0>;
			};

			uart3m0-cts {
				rockchip,pins = <0x00 0x12 0x02 0x9f>;
			};

			uart3m0-rts {
				rockchip,pins = <0x00 0x13 0x02 0x9f>;
			};
		};

		uart3-m1 {

			uart3m1-xfer {
				rockchip,pins = <0x01 0x0e 0x02 0xa0 0x01 0x0f 0x02 0xa0>;
				phandle = <0x4d>;
			};

			uart3m1-cts {
				rockchip,pins = <0x01 0x0c 0x02 0x9f>;
				phandle = <0x4e>;
			};

			uart3m1-rts {
				rockchip,pins = <0x01 0x0d 0x02 0x9f>;
				phandle = <0x4f>;
			};
		};

		uart4 {

			uart4-xfer {
				rockchip,pins = <0x01 0x1c 0x02 0xa0 0x01 0x1d 0x02 0xa0>;
				phandle = <0x50>;
			};

			uart4-cts {
				rockchip,pins = <0x01 0x1e 0x02 0x9f>;
				phandle = <0x51>;
			};

			uart4-rts {
				rockchip,pins = <0x01 0x1f 0x02 0x9f>;
				phandle = <0x52>;
			};
		};

		uart5 {

			uart5-xfer {
				rockchip,pins = <0x03 0x02 0x04 0xa0 0x03 0x01 0x04 0xa0>;
				phandle = <0x53>;
			};

			uart5-cts {
				rockchip,pins = <0x03 0x03 0x04 0x9f>;
				phandle = <0x54>;
			};

			uart5-rts {
				rockchip,pins = <0x03 0x05 0x04 0x9f>;
				phandle = <0x55>;
			};
		};

		spi0 {

			spi0-clk {
				rockchip,pins = <0x01 0x0f 0x03 0xa1>;
				phandle = <0x5e>;
			};

			spi0-csn {
				rockchip,pins = <0x01 0x0e 0x03 0xa1>;
				phandle = <0x5f>;
			};

			spi0-miso {
				rockchip,pins = <0x01 0x0d 0x03 0xa1>;
				phandle = <0x60>;
			};

			spi0-mosi {
				rockchip,pins = <0x01 0x0c 0x03 0xa1>;
				phandle = <0x61>;
			};

			spi0-clk-hs {
				rockchip,pins = <0x01 0x0f 0x03 0xa2>;
			};

			spi0-miso-hs {
				rockchip,pins = <0x01 0x0d 0x03 0xa2>;
			};

			spi0-mosi-hs {
				rockchip,pins = <0x01 0x0c 0x03 0xa2>;
			};
		};

		spi1 {

			spi1-clk {
				rockchip,pins = <0x03 0x0f 0x04 0xa1>;
				phandle = <0x62>;
			};

			spi1-csn0 {
				rockchip,pins = <0x03 0x09 0x04 0xa1>;
				phandle = <0x63>;
			};

			spi1-csn1 {
				rockchip,pins = <0x03 0x0a 0x02 0xa1>;
				phandle = <0x64>;
			};

			spi1-miso {
				rockchip,pins = <0x03 0x0e 0x04 0xa1>;
				phandle = <0x65>;
			};

			spi1-mosi {
				rockchip,pins = <0x03 0x0c 0x04 0xa1>;
				phandle = <0x66>;
			};

			spi1-clk-hs {
				rockchip,pins = <0x03 0x0f 0x04 0xa2>;
			};

			spi1-miso-hs {
				rockchip,pins = <0x03 0x0e 0x04 0xa2>;
			};

			spi1-mosi-hs {
				rockchip,pins = <0x03 0x0c 0x04 0xa2>;
			};
		};

		pdm {

			pdm-clk0m0 {
				rockchip,pins = <0x03 0x16 0x02 0x9f>;
			};

			pdm-clk0m1 {
				rockchip,pins = <0x02 0x16 0x01 0x9f>;
			};

			pdm-clk1 {
				rockchip,pins = <0x03 0x17 0x02 0x9f>;
			};

			pdm-sdi0m0 {
				rockchip,pins = <0x03 0x1b 0x02 0x9f>;
			};

			pdm-sdi0m1 {
				rockchip,pins = <0x02 0x15 0x02 0x9f>;
			};

			pdm-sdi1 {
				rockchip,pins = <0x03 0x18 0x02 0x9f>;
			};

			pdm-sdi2 {
				rockchip,pins = <0x03 0x19 0x02 0x9f>;
			};

			pdm-sdi3 {
				rockchip,pins = <0x03 0x1a 0x02 0x9f>;
			};

			pdm-clk0m0-sleep {
				rockchip,pins = <0x03 0x16 0x00 0xa3>;
			};

			pdm-clk0m1-sleep {
				rockchip,pins = <0x02 0x16 0x00 0xa3>;
			};

			pdm-clk1-sleep {
				rockchip,pins = <0x03 0x17 0x00 0xa3>;
			};

			pdm-sdi0m0-sleep {
				rockchip,pins = <0x03 0x1b 0x00 0xa3>;
			};

			pdm-sdi0m1-sleep {
				rockchip,pins = <0x02 0x15 0x00 0xa3>;
			};

			pdm-sdi1-sleep {
				rockchip,pins = <0x03 0x18 0x00 0xa3>;
			};

			pdm-sdi2-sleep {
				rockchip,pins = <0x03 0x19 0x00 0xa3>;
			};

			pdm-sdi3-sleep {
				rockchip,pins = <0x03 0x1a 0x00 0xa3>;
			};
		};

		i2s0 {

			i2s0-8ch-mclk {
				rockchip,pins = <0x03 0x11 0x02 0x9f>;
			};

			i2s0-8ch-sclktx {
				rockchip,pins = <0x03 0x13 0x02 0x9f>;
				phandle = <0x2f>;
			};

			i2s0-8ch-sclkrx {
				rockchip,pins = <0x03 0x0c 0x02 0x9f>;
				phandle = <0x30>;
			};

			i2s0-8ch-lrcktx {
				rockchip,pins = <0x03 0x12 0x02 0x9f>;
				phandle = <0x31>;
			};

			i2s0-8ch-lrckrx {
				rockchip,pins = <0x03 0x0d 0x02 0x9f>;
				phandle = <0x32>;
			};

			i2s0-8ch-sdo0 {
				rockchip,pins = <0x03 0x14 0x02 0x9f>;
				phandle = <0x33>;
			};

			i2s0-8ch-sdo1 {
				rockchip,pins = <0x03 0x10 0x02 0x9f>;
				phandle = <0x35>;
			};

			i2s0-8ch-sdo2 {
				rockchip,pins = <0x03 0x0f 0x02 0x9f>;
				phandle = <0x37>;
			};

			i2s0-8ch-sdo3 {
				rockchip,pins = <0x03 0x0e 0x02 0x9f>;
				phandle = <0x39>;
			};

			i2s0-8ch-sdi0 {
				rockchip,pins = <0x03 0x15 0x02 0x9f>;
				phandle = <0x34>;
			};

			i2s0-8ch-sdi1 {
				rockchip,pins = <0x03 0x0b 0x02 0x9f>;
				phandle = <0x36>;
			};

			i2s0-8ch-sdi2 {
				rockchip,pins = <0x03 0x09 0x02 0x9f>;
				phandle = <0x38>;
			};

			i2s0-8ch-sdi3 {
				rockchip,pins = <0x03 0x08 0x02 0x9f>;
				phandle = <0x3a>;
			};
		};

		i2s1 {

			i2s1-2ch-mclk {
				rockchip,pins = <0x02 0x13 0x01 0x9f>;
			};

			i2s1-2ch-sclk {
				rockchip,pins = <0x02 0x12 0x01 0x9f>;
				phandle = <0x3b>;
			};

			i2s1-2ch-lrck {
				rockchip,pins = <0x02 0x11 0x01 0x9f>;
				phandle = <0x3c>;
			};

			i2s1-2ch-sdi {
				rockchip,pins = <0x02 0x15 0x01 0x9f>;
				phandle = <0x3d>;
			};

			i2s1-2ch-sdo {
				rockchip,pins = <0x02 0x14 0x01 0x9f>;
				phandle = <0x3e>;
			};
		};

		i2s2 {

			i2s2-2ch-mclk {
				rockchip,pins = <0x03 0x01 0x02 0x9f>;
			};

			i2s2-2ch-sclk {
				rockchip,pins = <0x03 0x02 0x02 0x9f>;
				phandle = <0x3f>;
			};

			i2s2-2ch-lrck {
				rockchip,pins = <0x03 0x03 0x02 0x9f>;
				phandle = <0x40>;
			};

			i2s2-2ch-sdi {
				rockchip,pins = <0x03 0x05 0x02 0x9f>;
				phandle = <0x41>;
			};

			i2s2-2ch-sdo {
				rockchip,pins = <0x03 0x07 0x02 0x9f>;
				phandle = <0x42>;
			};
		};

		sdmmc {

			sdmmc-clk {
				rockchip,pins = <0x01 0x1e 0x01 0xa4>;
				phandle = <0x79>;
			};

			sdmmc-cmd {
				rockchip,pins = <0x01 0x1f 0x01 0xa2>;
				phandle = <0x7a>;
			};

			sdmmc-det {
				rockchip,pins = <0x00 0x03 0x01 0xa2>;
				phandle = <0x7b>;
			};

			sdmmc-bus1 {
				rockchip,pins = <0x01 0x1a 0x01 0xa2>;
			};

			sdmmc-bus4 {
				rockchip,pins = <0x01 0x1a 0x01 0xa2 0x01 0x1b 0x01 0xa2 0x01 0x1c 0x01 0xa2 0x01 0x1d 0x01 0xa2>;
				phandle = <0x7c>;
			};
		};

		sdio {

			sdio-clk {
				rockchip,pins = <0x01 0x15 0x01 0x9f>;
				phandle = <0x80>;
			};

			sdio-cmd {
				rockchip,pins = <0x01 0x14 0x01 0xa0>;
				phandle = <0x7f>;
			};

			sdio-bus4 {
				rockchip,pins = <0x01 0x16 0x01 0xa0 0x01 0x17 0x01 0xa0 0x01 0x18 0x01 0xa0 0x01 0x19 0x01 0xa0>;
				phandle = <0x7e>;
			};
		};

		emmc {

			emmc-clk {
				rockchip,pins = <0x01 0x09 0x02 0xa4>;
				phandle = <0x82>;
			};

			emmc-cmd {
				rockchip,pins = <0x01 0x0a 0x02 0xa2>;
				phandle = <0x83>;
			};

			emmc-rstnout {
				rockchip,pins = <0x01 0x0b 0x02 0x9f>;
			};

			emmc-bus1 {
				rockchip,pins = <0x01 0x00 0x02 0xa2>;
			};

			emmc-bus4 {
				rockchip,pins = <0x01 0x00 0x02 0xa2 0x01 0x01 0x02 0xa2 0x01 0x02 0x02 0xa2 0x01 0x03 0x02 0xa2>;
			};

			emmc-bus8 {
				rockchip,pins = <0x01 0x00 0x02 0xa2 0x01 0x01 0x02 0xa2 0x01 0x02 0x02 0xa2 0x01 0x03 0x02 0xa2 0x01 0x04 0x02 0xa2 0x01 0x05 0x02 0xa2 0x01 0x06 0x02 0xa2 0x01 0x07 0x02 0xa2>;
				phandle = <0x84>;
			};

			emmc-reset {
				rockchip,pins = <0x01 0x0b 0x00 0x9f>;
				phandle = <0xa7>;
			};
		};

		flash {

			flash-cs0 {
				rockchip,pins = <0x01 0x08 0x01 0x9f>;
				phandle = <0x8c>;
			};

			flash-rdy {
				rockchip,pins = <0x01 0x09 0x01 0x9f>;
				phandle = <0x8e>;
			};

			flash-dqs {
				rockchip,pins = <0x01 0x0a 0x01 0x9f>;
				phandle = <0x90>;
			};

			flash-ale {
				rockchip,pins = <0x01 0x0b 0x01 0x9f>;
				phandle = <0x89>;
			};

			flash-cle {
				rockchip,pins = <0x01 0x0c 0x01 0x9f>;
				phandle = <0x8b>;
			};

			flash-wrn {
				rockchip,pins = <0x01 0x0d 0x01 0x9f>;
				phandle = <0x8f>;
			};

			flash-csl {
				rockchip,pins = <0x01 0x0e 0x01 0x9f>;
			};

			flash-rdn {
				rockchip,pins = <0x01 0x0f 0x01 0x9f>;
				phandle = <0x8d>;
			};

			flash-bus8 {
				rockchip,pins = <0x01 0x00 0x01 0xa5 0x01 0x01 0x01 0xa5 0x01 0x02 0x01 0xa5 0x01 0x03 0x01 0xa5 0x01 0x04 0x01 0xa5 0x01 0x05 0x01 0xa5 0x01 0x06 0x01 0xa5 0x01 0x07 0x01 0xa5>;
				phandle = <0x8a>;
			};
		};

		sfc {

			sfc-bus4 {
				rockchip,pins = <0x01 0x00 0x03 0x9f 0x01 0x01 0x03 0x9f 0x01 0x02 0x03 0x9f 0x01 0x03 0x03 0x9f>;
				phandle = <0x88>;
			};

			sfc-bus2 {
				rockchip,pins = <0x01 0x00 0x03 0x9f 0x01 0x01 0x03 0x9f>;
			};

			sfc-cs0 {
				rockchip,pins = <0x01 0x04 0x03 0x9f>;
				phandle = <0x87>;
			};

			sfc-clk {
				rockchip,pins = <0x01 0x09 0x03 0x9f>;
				phandle = <0x86>;
			};
		};

		lcdc {

			lcdc-rgb-dclk-pin {
				rockchip,pins = <0x03 0x00 0x01 0xa6>;
			};

			lcdc-rgb-m0-hsync-pin {
				rockchip,pins = <0x03 0x01 0x01 0xa6>;
			};

			lcdc-rgb-m0-vsync-pin {
				rockchip,pins = <0x03 0x02 0x01 0xa6>;
			};

			lcdc-rgb-m0-den-pin {
				rockchip,pins = <0x03 0x03 0x01 0xa6>;
			};

			lcdc-rgb888-m0-data-pins {
				rockchip,pins = <0x03 0x07 0x01 0xa4 0x03 0x06 0x01 0xa4 0x03 0x05 0x01 0xa4 0x03 0x04 0x01 0xa4 0x03 0x0b 0x01 0xa4 0x03 0x0a 0x01 0xa4 0x03 0x09 0x01 0xa4 0x03 0x08 0x01 0xa4 0x03 0x0f 0x01 0xa4 0x03 0x0e 0x01 0xa4 0x03 0x0d 0x01 0xa4 0x03 0x0c 0x01 0xa4 0x03 0x13 0x01 0xa4 0x03 0x12 0x01 0xa4 0x03 0x11 0x01 0xa4 0x03 0x10 0x01 0xa4 0x03 0x17 0x01 0xa4 0x03 0x16 0x01 0xa4 0x03 0x15 0x01 0xa4 0x03 0x14 0x01 0xa4 0x03 0x1b 0x01 0xa4 0x03 0x1a 0x01 0xa4 0x03 0x19 0x01 0xa4 0x03 0x18 0x01 0xa4>;
			};

			lcdc-rgb666-m0-data-pins {
				rockchip,pins = <0x03 0x07 0x01 0xa4 0x03 0x06 0x01 0xa4 0x03 0x05 0x01 0xa4 0x03 0x04 0x01 0xa4 0x03 0x0b 0x01 0xa4 0x03 0x0a 0x01 0xa4 0x03 0x09 0x01 0xa4 0x03 0x08 0x01 0xa4 0x03 0x0f 0x01 0xa4 0x03 0x0e 0x01 0xa4 0x03 0x0d 0x01 0xa4 0x03 0x0c 0x01 0xa4 0x03 0x13 0x01 0xa4 0x03 0x12 0x01 0xa4 0x03 0x11 0x01 0xa4 0x03 0x10 0x01 0xa4 0x03 0x15 0x01 0xa4 0x03 0x14 0x01 0xa4>;
			};

			lcdc-rgb565-m0-data-pins {
				rockchip,pins = <0x03 0x07 0x01 0xa4 0x03 0x06 0x01 0xa4 0x03 0x05 0x01 0xa4 0x03 0x04 0x01 0xa4 0x03 0x0b 0x01 0xa4 0x03 0x0a 0x01 0xa4 0x03 0x09 0x01 0xa4 0x03 0x08 0x01 0xa4 0x03 0x0f 0x01 0xa4 0x03 0x0e 0x01 0xa4 0x03 0x0d 0x01 0xa4 0x03 0x0c 0x01 0xa4 0x03 0x13 0x01 0xa4 0x03 0x12 0x01 0xa4 0x03 0x11 0x01 0xa4 0x03 0x10 0x01 0xa4>;
			};

			lcdc-rgb888-m1-data-pins {
				rockchip,pins = <0x03 0x06 0x01 0xa4 0x03 0x04 0x01 0xa4 0x03 0x0b 0x01 0xa4 0x03 0x0a 0x01 0xa4 0x03 0x0d 0x01 0xa4 0x03 0x13 0x01 0xa4 0x03 0x12 0x01 0xa4 0x03 0x11 0x01 0xa4 0x03 0x10 0x01 0xa4 0x03 0x17 0x01 0xa4 0x03 0x16 0x01 0xa4 0x03 0x15 0x01 0xa4 0x03 0x14 0x01 0xa4 0x03 0x1b 0x01 0xa4 0x03 0x1a 0x01 0xa4 0x03 0x19 0x01 0xa4 0x03 0x18 0x01 0xa4>;
			};

			lcdc-rgb666-m1-data-pins {
				rockchip,pins = <0x03 0x06 0x01 0xa4 0x03 0x04 0x01 0xa4 0x03 0x0b 0x01 0xa4 0x03 0x0a 0x01 0xa4 0x03 0x0d 0x01 0xa4 0x03 0x13 0x01 0xa4 0x03 0x12 0x01 0xa4 0x03 0x11 0x01 0xa4 0x03 0x10 0x01 0xa4 0x03 0x15 0x01 0xa4 0x03 0x14 0x01 0xa4>;
			};

			lcdc-rgb565-m1-data-pins {
				rockchip,pins = <0x03 0x06 0x01 0xa4 0x03 0x04 0x01 0xa4 0x03 0x0b 0x01 0xa4 0x03 0x0a 0x01 0xa4 0x03 0x0d 0x01 0xa4 0x03 0x13 0x01 0xa4 0x03 0x12 0x01 0xa4 0x03 0x11 0x01 0xa4 0x03 0x10 0x01 0xa4>;
			};
		};

		pwm0 {

			pwm0-pin {
				rockchip,pins = <0x00 0x0f 0x01 0x9f>;
				phandle = <0x67>;
			};
		};

		pwm1 {

			pwm1-pin {
				rockchip,pins = <0x00 0x10 0x01 0x9f>;
				phandle = <0x68>;
			};
		};

		pwm2 {

			pwm2-pin {
				rockchip,pins = <0x02 0x0d 0x01 0x9f>;
				phandle = <0x69>;
			};
		};

		pwm3 {

			pwm3-pin {
				rockchip,pins = <0x00 0x11 0x01 0x9f>;
				phandle = <0x6a>;
			};
		};

		pwm4 {

			pwm4-pin {
				rockchip,pins = <0x03 0x12 0x03 0x9f>;
				phandle = <0x6b>;
			};
		};

		pwm5 {

			pwm5-pin {
				rockchip,pins = <0x03 0x13 0x03 0x9f>;
				phandle = <0x6c>;
			};
		};

		pwm6 {

			pwm6-pin {
				rockchip,pins = <0x03 0x14 0x03 0x9f>;
				phandle = <0x6d>;
			};
		};

		pwm7 {

			pwm7-pin {
				rockchip,pins = <0x03 0x15 0x03 0x9f>;
				phandle = <0x6e>;
			};
		};

		gmac {

			rmii-pins {
				rockchip,pins = <0x02 0x00 0x02 0xa6 0x02 0x01 0x02 0xa6 0x02 0x02 0x02 0xa6 0x02 0x03 0x02 0x9f 0x02 0x04 0x02 0x9f 0x02 0x05 0x02 0x9f 0x02 0x06 0x02 0x9f 0x02 0x07 0x02 0x9f 0x02 0x09 0x02 0x9f>;
				phandle = <0x76>;
			};

			mac-refclk-12ma {
				rockchip,pins = <0x02 0x0a 0x02 0xa6>;
				phandle = <0x77>;
			};

			mac-refclk {
				rockchip,pins = <0x02 0x0a 0x02 0x9f>;
			};
		};

		cif-m0 {

			cif-clkout-m0 {
				rockchip,pins = <0x02 0x0b 0x01 0x9f>;
			};

			dvp-d2d9-m0 {
				rockchip,pins = <0x02 0x00 0x01 0x9f 0x02 0x01 0x01 0x9f 0x02 0x02 0x01 0x9f 0x02 0x03 0x01 0x9f 0x02 0x04 0x01 0x9f 0x02 0x05 0x01 0x9f 0x02 0x06 0x01 0x9f 0x02 0x07 0x01 0x9f 0x02 0x08 0x01 0x9f 0x02 0x09 0x01 0x9f 0x02 0x0a 0x01 0x9f 0x02 0x0b 0x01 0x9f>;
			};

			dvp-d0d1-m0 {
				rockchip,pins = <0x02 0x0c 0x01 0x9f 0x02 0x0e 0x01 0x9f>;
			};

			d10-d11-m0 {
				rockchip,pins = <0x02 0x0f 0x01 0x9f 0x02 0x10 0x01 0x9f>;
			};
		};

		cif-m1 {

			cif-clkout-m1 {
				rockchip,pins = <0x03 0x18 0x03 0x9f>;
			};

			dvp-d2d9-m1 {
				rockchip,pins = <0x03 0x03 0x03 0x9f 0x03 0x05 0x03 0x9f 0x03 0x07 0x03 0x9f 0x03 0x08 0x03 0x9f 0x03 0x09 0x03 0x9f 0x03 0x0c 0x03 0x9f 0x03 0x0e 0x03 0x9f 0x03 0x0f 0x03 0x9f 0x03 0x19 0x03 0x9f 0x03 0x1a 0x03 0x9f 0x03 0x1b 0x03 0x9f 0x03 0x18 0x03 0x9f>;
			};

			dvp-d0d1-m1 {
				rockchip,pins = <0x03 0x01 0x03 0x9f 0x03 0x02 0x03 0x9f>;
			};

			d10-d11-m1 {
				rockchip,pins = <0x03 0x16 0x03 0x9f 0x03 0x17 0x03 0x9f>;
			};
		};

		isp {

			isp-prelight {
				rockchip,pins = <0x03 0x19 0x04 0x9f>;
			};
		};

		pmic {

			pmic_int {
				rockchip,pins = <0x00 0x07 0x00 0xa0>;
				phandle = <0x58>;
			};
		};

		leds {

			blue-led {
				rockchip,pins = <0x01 0x0d 0x00 0x9f>;
				phandle = <0xab>;
			};

			green-led {
				rockchip,pins = <0x01 0x0c 0x00 0x9f>;
				phandle = <0xac>;
			};
		};

		sdio-pwrseq {

			wifi-enable-h {
				rockchip,pins = <0x00 0x02 0x00 0x9f>;
				phandle = <0xad>;
			};
		};
	};

	emmc-pwrseq {
		compatible = "mmc-pwrseq-emmc";
		pinctrl-0 = <0xa7>;
		pinctrl-names = "default";
		reset-gpios = <0xa8 0x0b 0x00>;
		phandle = <0x85>;
	};

	vcc5v0-sys-regulator {
		compatible = "regulator-fixed";
		regulator-name = "vcc5v0_sys";
		regulator-always-on;
		regulator-boot-on;
		regulator-min-microvolt = <0x4c4b40>;
		regulator-max-microvolt = <0x4c4b40>;
		vin-supply = <0xa9>;
		phandle = <0x59>;
	};

	chosen {
		stdout-path = "serial2:115200n8";
	};

	dc-12v-regulator {
		compatible = "regulator-fixed";
		regulator-name = "dc_12v";
		regulator-always-on;
		regulator-boot-on;
		regulator-min-microvolt = <0xb71b00>;
		regulator-max-microvolt = <0xb71b00>;
		phandle = <0xae>;
	};

	adc-keys {
		compatible = "adc-keys";
		io-channels = <0xaa 0x02>;
		io-channel-names = "buttons";
		keyup-threshold-microvolt = <0x16e360>;
		poll-interval = <0x64>;

		button-recovery {
			label = "Recovery";
			linux,code = <0x168>;
			press-threshold-microvolt = <0x4650>;
		};
	};

	leds {
		compatible = "gpio-leds";
		pinctrl-names = "default";
		pinctrl-0 = <0xab 0xac>;

		blue-led {
			color = <0x03>;
			default-state = "on";
			function = "heartbeat";
			gpios = <0xa8 0x0d 0x00>;
			label = "px30-mb-jd4:blue:work";
			linux,default-trigger = "heartbeat";
		};

		green-led {
			color = <0x02>;
			default-state = "on";
			function = "power";
			gpios = <0xa8 0x0c 0x00>;
			label = "px30-mb-jd4:blue:diy";
			linux,default-trigger = "default-on";
		};
	};

	sdio-pwrseq {
		compatible = "mmc-pwrseq-simple";
		pinctrl-names = "default";
		pinctrl-0 = <0xad>;
		reset-gpios = <0x57 0x02 0x01>;
		phandle = <0x81>;
	};

	vcc5v0-baseboard-regulator {
		compatible = "regulator-fixed";
		regulator-name = "vcc5v0_baseboard";
		regulator-always-on;
		regulator-boot-on;
		regulator-min-microvolt = <0x4c4b40>;
		regulator-max-microvolt = <0x4c4b40>;
		vin-supply = <0xae>;
		phandle = <0xa9>;
	};
};
